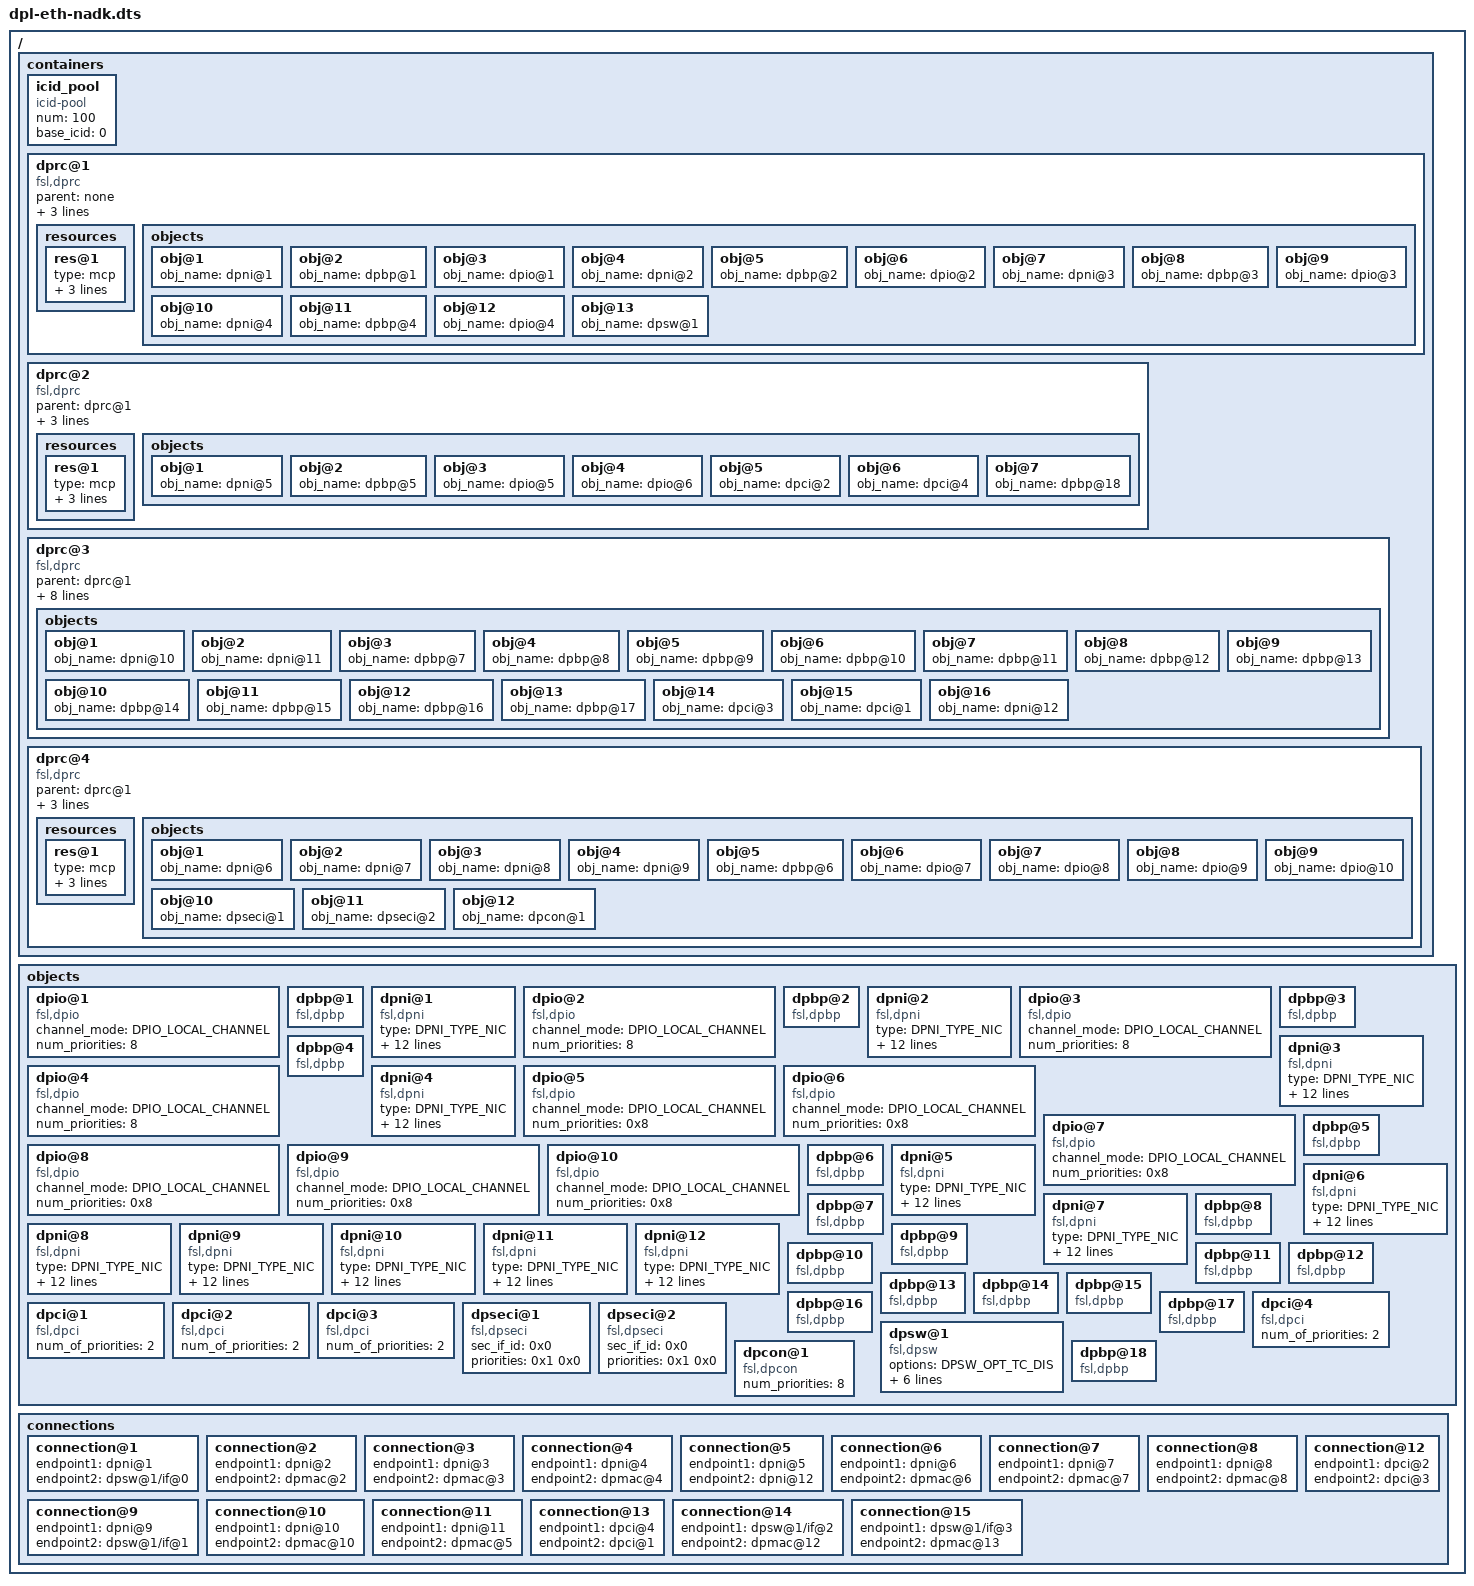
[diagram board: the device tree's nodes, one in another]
/*
 * Datapath layout file for LS2085A.
 * Contains 4 containers-- one for host Linux, two for NADK & one for AIOP
 *
 * Copyright 2013 Freescale Semiconductor, Inc.
 */

/dts-v1/;
/ {
	containers {
		icid_pool {
			compatible = "icid-pool";
			num = <100>;
			base_icid = <0>;
		};
		dprc@1 {
			compatible = "fsl,dprc";
			parent = "none";
			options = "DPRC_CFG_OPT_SPAWN_ALLOWED" , "DPRC_CFG_OPT_ALLOC_ALLOWED";
			portal_id = <0>;
			resources {
				res@1 {
					type = "mcp";
					num = <16>;
					options = <1>;
					id_base_align = <15>;
				};
			};
			objects {
				obj@1{
					obj_name = "dpni@1";
				};
				obj@2{
					obj_name = "dpbp@1";
				};
				obj@3{
					obj_name = "dpio@1";
				};
				obj@4{
					obj_name = "dpni@2";
				};
				obj@5{
					obj_name = "dpbp@2";
				};
				obj@6{
					obj_name = "dpio@2";
				};
				obj@7{
					obj_name = "dpni@3";
				};
				obj@8{
					obj_name = "dpbp@3";
				};
				obj@9{
					obj_name = "dpio@3";
				};
				obj@10{
					obj_name = "dpni@4";
				};
				obj@11{
					obj_name = "dpbp@4";
				};
				obj@12{
					obj_name = "dpio@4";
				};
				obj@13{
					obj_name = "dpsw@1";
				};
			};
		};

		dprc@2 {
			compatible = "fsl,dprc";
			parent = "dprc@1";
			options = "DPRC_CFG_OPT_SPAWN_ALLOWED", "DPRC_CFG_OPT_ALLOC_ALLOWED";
			portal_id = <0x5>;

			resources {

				res@1 {
					type = "mcp";
					num = <0x1>;
					options = <0x1>;
					id_base_align = <0x2>;
				};
			};

			objects {

				obj@1 {
					obj_name = "dpni@5";
				};

				obj@2 {
					obj_name = "dpbp@5";
				};

				obj@3 {
					obj_name = "dpio@5";
				};

				obj@4 {
					obj_name = "dpio@6";
				};

				obj@5{
					obj_name = "dpci@2";
				};

				obj@6{
					obj_name = "dpci@4";
				};

				obj@7 {
					obj_name = "dpbp@18";
				};

			};
		};

		dprc@3 {
			compatible = "fsl,dprc";
			parent = "dprc@1";
			options = "DPRC_CFG_OPT_TOPOLOGY_CHANGES_ALLOWED" , "DPRC_CFG_OPT_IOMMU_BYPASS" , "DPRC_CFG_OPT_SPAWN_ALLOWED" , "DPRC_CFG_OPT_ALLOC_ALLOWED" , "DPRC_CFG_OPT_AIOP" , "DPRC_CFG_OPT_OBJ_CREATE_ALLOWED";
			portal_id = <0x1>;
			objects {
				obj@1{
					obj_name = "dpni@10";
				};
				obj@2{
					obj_name = "dpni@11";
				};
				obj@3{
					obj_name = "dpbp@7";
				};
				obj@4{
					obj_name = "dpbp@8";
				};
				obj@5{
					obj_name = "dpbp@9";
				};
				obj@6{
					obj_name = "dpbp@10";
				};
				obj@7{
					obj_name = "dpbp@11";
				};
				obj@8{
					obj_name = "dpbp@12";
				};
				obj@9{
					obj_name = "dpbp@13";
				};
				obj@10{
					obj_name = "dpbp@14";
				};
				obj@11{
					obj_name = "dpbp@15";
				};
				obj@12{
					obj_name = "dpbp@16";
				};
				obj@13{
					obj_name = "dpbp@17";
				};
				obj@14{
					obj_name = "dpci@3";
				};
				obj@15{
					obj_name = "dpci@1";
				};
				obj@16{
					obj_name = "dpni@12";
				};
			};
		};

		dprc@4 {
			compatible = "fsl,dprc";
			parent = "dprc@1";
			options = "DPRC_CFG_OPT_SPAWN_ALLOWED", "DPRC_CFG_OPT_ALLOC_ALLOWED";
			portal_id = <0x3>;

			resources {

				res@1 {
					type = "mcp";
					num = <0x1>;
					options = <0x1>;
					id_base_align = <0x4>;
				};
			};

			objects {

				obj@1 {
					obj_name = "dpni@6";
				};

				obj@2 {
					obj_name = "dpni@7";
				};

				obj@3 {
					obj_name = "dpni@8";
				};

				obj@4 {
					obj_name = "dpni@9";
				};

				obj@5 {
					obj_name = "dpbp@6";
				};

				obj@6 {
					obj_name = "dpio@7";
				};

				obj@7 {
					obj_name = "dpio@8";
				};

				obj@8 {
					obj_name = "dpio@9";
				};

				obj@9 {
					obj_name = "dpio@10";
				};
				obj@10 {
					obj_name = "dpseci@1";
				};
				obj@11 {
					obj_name = "dpseci@2";
				};
				obj@12 {
					obj_name = "dpcon@1";
				};
			};
		};
	};

	objects {
		dpio@1 {
			compatible = "fsl,dpio";
			channel_mode = "DPIO_LOCAL_CHANNEL";
			num_priorities = <8>;
		};
		dpbp@1 {
			compatible = "fsl,dpbp";
		};
		dpni@1{
			compatible = "fsl,dpni";
			type = "DPNI_TYPE_NIC";
			mac_addr = <0x02 0x00 0xc0 0xa8 0x47 0x01>;
			max_senders = <0>;
			options = "DPNI_OPT_MULTICAST_FILTER", "DPNI_OPT_UNICAST_FILTER";
			max_tcs = <0>;
			max_dist_per_tc = <0 0 0>;
			max_unicast_filters = <0>;
			max_multicast_filters = <0>;
			max_vlan_filters = <0>;
			max_qos_entries = <0>;
			max_qos_key_size = <0>;
			max_dist_key_size = <0>;
		};
		dpio@2 {
			compatible = "fsl,dpio";
			channel_mode = "DPIO_LOCAL_CHANNEL";
			num_priorities = <8>;
		};
		dpbp@2 {
			compatible = "fsl,dpbp";
		};
		dpni@2 {
			compatible = "fsl,dpni";
			type = "DPNI_TYPE_NIC";
			mac_addr = <0x02 0x00 0xc0 0xa8 0x47 0x02>;
			max_senders = <1>;
			options = "DPNI_OPT_MULTICAST_FILTER", "DPNI_OPT_UNICAST_FILTER";
			max_tcs = <1>;
			max_dist_per_tc = <1 0 0>;
			max_unicast_filters = <0>;
			max_multicast_filters = <0>;
			max_vlan_filters = <0>;
			max_qos_entries = <0>;
			max_qos_key_size = <0>;
			max_dist_key_size = <0>;
		};
		dpio@3 {
			compatible = "fsl,dpio";
			channel_mode = "DPIO_LOCAL_CHANNEL";
			num_priorities = <8>;
		};
		dpbp@3 {
			compatible = "fsl,dpbp";
		};
		dpni@3 {
			compatible = "fsl,dpni";
			type = "DPNI_TYPE_NIC";
			mac_addr = <0x02 0x00 0xc0 0xa8 0x47 0x03>;
			max_senders = <1>;
			options = "DPNI_OPT_MULTICAST_FILTER", "DPNI_OPT_UNICAST_FILTER";
			max_tcs = <1>;
			max_dist_per_tc = <1 0 0>;
			max_unicast_filters = <0>;
			max_multicast_filters = <0>;
			max_vlan_filters = <0>;
			max_qos_entries = <0>;
			max_qos_key_size = <0>;
			max_dist_key_size = <0>;
		};
		dpio@4 {
			compatible = "fsl,dpio";
			channel_mode = "DPIO_LOCAL_CHANNEL";
			num_priorities = <8>;
		};
		dpbp@4 {
			compatible = "fsl,dpbp";
		};
		dpni@4 {
			compatible = "fsl,dpni";
			type = "DPNI_TYPE_NIC";
			mac_addr = <0x02 0x00 0xc0 0xa8 0x47 0x04>;
			max_senders = <1>;
			options = "DPNI_OPT_MULTICAST_FILTER", "DPNI_OPT_UNICAST_FILTER";
			max_tcs = <1>;
			max_dist_per_tc = <1 0 0>;
			max_unicast_filters = <0>;
			max_multicast_filters = <0>;
			max_vlan_filters = <0>;
			max_qos_entries = <0>;
			max_qos_key_size = <0>;
			max_dist_key_size = <0>;
		};

		dpio@5 {
			compatible = "fsl,dpio";
			channel_mode = "DPIO_LOCAL_CHANNEL";
			num_priorities = <0x8>;
		};

		dpio@6 {
			compatible = "fsl,dpio";
			channel_mode = "DPIO_LOCAL_CHANNEL";
			num_priorities = <0x8>;
		};

		dpio@7 {
			compatible = "fsl,dpio";
			channel_mode = "DPIO_LOCAL_CHANNEL";
			num_priorities = <0x8>;
		};

		dpio@8 {
			compatible = "fsl,dpio";
			channel_mode = "DPIO_LOCAL_CHANNEL";
			num_priorities = <0x8>;
		};

		dpio@9 {
			compatible = "fsl,dpio";
			channel_mode = "DPIO_LOCAL_CHANNEL";
			num_priorities = <0x8>;
		};

		dpio@10 {
			compatible = "fsl,dpio";
			channel_mode = "DPIO_LOCAL_CHANNEL";
			num_priorities = <0x8>;
		};

		dpbp@5 {
			compatible = "fsl,dpbp";
		};

		dpbp@6 {
			compatible = "fsl,dpbp";
		};

		dpni@5 {
			compatible = "fsl,dpni";
			type = "DPNI_TYPE_NIC";
			mac_addr = <0x0 0x0 0x5 0x0 0x0 0x5>;
			max_senders = <1>;
			options = "DPNI_OPT_MULTICAST_FILTER" , "DPNI_OPT_UNICAST_FILTER";
			max_tcs = <1>;
			max_dist_per_tc = <1 0 0>;
			max_unicast_filters = <16>;
			max_multicast_filters = <16>;
			max_vlan_filters = <0x0>;
			max_qos_entries = <0x0>;
			max_qos_key_size = <0x0>;
			max_dist_key_size = <0x0>;
		};

		dpni@6 {
			compatible = "fsl,dpni";
			type = "DPNI_TYPE_NIC";
			mac_addr = <0x0 0x0 0x0 0x0 0x0 0x6>;
			max_senders = <1>;
			options = "DPNI_OPT_MULTICAST_FILTER" , "DPNI_OPT_UNICAST_FILTER" , "DPNI_OPT_DIST_HASH";
			max_tcs = <1>;
			max_dist_per_tc = <3>;
			max_unicast_filters = <16>;
			max_multicast_filters = <16>;
			max_vlan_filters = <0x0>;
			max_qos_entries = <0x0>;
			max_qos_key_size = <0x0>;
			max_dist_key_size = <0x0>;
		};

		dpni@7 {
			compatible = "fsl,dpni";
			type = "DPNI_TYPE_NIC";
			mac_addr = <0x0 0x0 0x0 0x0 0x0 0x7>;
			max_senders = <1>;
			options = "DPNI_OPT_MULTICAST_FILTER" , "DPNI_OPT_UNICAST_FILTER" , "DPNI_OPT_DIST_HASH";
			max_tcs = <1>;
			max_dist_per_tc = <3>;
			max_unicast_filters = <16>;
			max_multicast_filters = <16>;
			max_vlan_filters = <0x0>;
			max_qos_entries = <0x0>;
			max_qos_key_size = <0x0>;
			max_dist_key_size = <0x0>;
		};

		dpni@8 {
			compatible = "fsl,dpni";
			type = "DPNI_TYPE_NIC";
			mac_addr = <0x0 0x0 0x0 0x0 0x0 0x8>;
			max_senders = <1>;
			options = "DPNI_OPT_MULTICAST_FILTER" , "DPNI_OPT_UNICAST_FILTER" , "DPNI_OPT_DIST_HASH";
			max_tcs = <1>;
			max_dist_per_tc = <3>;
			max_unicast_filters = <16>;
			max_multicast_filters = <16>;
			max_vlan_filters = <0x0>;
			max_qos_entries = <0x0>;
			max_qos_key_size = <0x0>;
			max_dist_key_size = <0x0>;
		};

		dpni@9 {
			compatible = "fsl,dpni";
			type = "DPNI_TYPE_NIC";
			mac_addr = <0x0 0x0 0x0 0x0 0x0 0x9>;
			max_senders = <1>;
			options = "DPNI_OPT_MULTICAST_FILTER" , "DPNI_OPT_UNICAST_FILTER" , "DPNI_OPT_DIST_HASH";
			max_tcs = <1>;
			max_dist_per_tc = <3>;
			max_unicast_filters = <16>;
			max_multicast_filters = <16>;
			max_vlan_filters = <0x0>;
			max_qos_entries = <0x0>;
			max_qos_key_size = <0x0>;
			max_dist_key_size = <0x0>;
		};

		dpni@10{
			compatible = "fsl,dpni";
			type = "DPNI_TYPE_NIC";
			mac_addr = < 0x0 0x0 0x1 0x0 0x0 0x1 >;
			max_senders = <0>;
			options = "DPNI_OPT_MULTICAST_FILTER" , "DPNI_OPT_UNICAST_FILTER" , "DPNI_OPT_DIST_HASH";
			max_tcs = <0>;
			max_dist_per_tc = < 0 0 0 0 0 0 0 0 >;
			max_unicast_filters = <0>;
			max_multicast_filters = <0>;
			max_vlan_filters = <0>;
			max_qos_entries = <0>;
			max_qos_key_size = <0>;
			max_dist_key_size = <0>;
		};

		dpni@11{
			compatible = "fsl,dpni";
			type = "DPNI_TYPE_NIC";
			mac_addr = < 0x0 0x0 0x2 0x0 0x0 0x2 >;
			max_senders = <0>;
			options = "DPNI_OPT_MULTICAST_FILTER" , "DPNI_OPT_UNICAST_FILTER" , "DPNI_OPT_DIST_HASH";
			max_tcs = <0>;
			max_dist_per_tc = < 0 0 0 0 0 0 0 0 >;
			max_unicast_filters = <0>;
			max_multicast_filters = <0>;
			max_vlan_filters = <0>;
			max_qos_entries = <0>;
			max_qos_key_size = <0>;
			max_dist_key_size = <0>;
		};

		dpni@12 {
			compatible = "fsl,dpni";
			type = "DPNI_TYPE_NIC";
			mac_addr = < 0x0 0x0 0xC 0x0 0x0 0xC >;
			max_senders = <0>;
			options = "DPNI_OPT_MULTICAST_FILTER" , "DPNI_OPT_UNICAST_FILTER";
			max_tcs = <0>;
			max_dist_per_tc = < 0 0 0 0 0 0 0 0 >;
			max_unicast_filters = <0>;
			max_multicast_filters = <0>;
			max_vlan_filters = <0>;
			max_qos_entries = <0>;
			max_qos_key_size = <0>;
			max_dist_key_size = <0>;
		};


		dpbp@7 {
			compatible = "fsl,dpbp";
		};

		dpbp@8 {
			compatible = "fsl,dpbp";
		};

		dpbp@9 {
			compatible = "fsl,dpbp";
		};

		dpbp@10 {
			compatible = "fsl,dpbp";
		};

		dpbp@11 {
			compatible = "fsl,dpbp";
		};

		dpbp@12 {
			compatible = "fsl,dpbp";
		};

		dpbp@13 {
			compatible = "fsl,dpbp";
		};

		dpbp@14 {
			compatible = "fsl,dpbp";
		};

		dpbp@15 {
			compatible = "fsl,dpbp";
		};

		dpbp@16 {
			compatible = "fsl,dpbp";
		};

		dpbp@17 {
			compatible = "fsl,dpbp";
		};

		dpci@4{
			compatible = "fsl,dpci";
			num_of_priorities = <2>;
		};
		dpci@1{
			compatible = "fsl,dpci";
			num_of_priorities = <2>;
		};

		dpci@2{
			compatible = "fsl,dpci";
			num_of_priorities = <2>;
		};
		dpci@3{
			compatible = "fsl,dpci";
			num_of_priorities = <2>;
		};
		dpseci@1 {
			compatible = "fsl,dpseci";
			sec_if_id = <0x0>;
			priorities = <0x1 0x0>;
		};
		dpseci@2 {
			compatible = "fsl,dpseci";
			sec_if_id = <0x0>;
			priorities = <0x1 0x0>;
		};

		dpsw@1 {
			compatible = "fsl,dpsw";
			options = "DPSW_OPT_TC_DIS";
			max_vlans = <0x10>;
			max_fdbs = <0x1>;
			num_fdb_entries = <0x400>;
			fdb_aging_time = <0x12c>;
			num_ifs = <0x4>;
			max_fdb_mc_groups = <32>;
		};
		dpcon@1 {
			compatible = "fsl,dpcon";
			num_priorities = <8>;
		};

		dpbp@18 {
			compatible = "fsl,dpbp";
		};

	};

	connections {
		connection@1{
			endpoint1 = "dpni@1";
			endpoint2 = "dpsw@1/if@0";
		};
		connection@2{
			endpoint1 = "dpni@2";
			endpoint2 = "dpmac@2";
		};
		connection@3{
			endpoint1 = "dpni@3";
			endpoint2 = "dpmac@3";
		};
		connection@4{
			endpoint1 = "dpni@4";
			endpoint2 = "dpmac@4";
		};
		connection@5 {
			endpoint1 = "dpni@5";
			endpoint2 = "dpni@12";
		};
		connection@6{
			endpoint1 = "dpni@6";
			endpoint2 = "dpmac@6";
		};
		connection@7{
			endpoint1 = "dpni@7";
			endpoint2 = "dpmac@7";
		};
		connection@8{
			endpoint1 = "dpni@8";
			endpoint2 = "dpmac@8";
		};
		connection@9{
			endpoint1 = "dpni@9";
			endpoint2 = "dpsw@1/if@1";
		};
		connection@10 {
			endpoint1 = "dpni@10";
			endpoint2 = "dpmac@10";
		};
		connection@11 {
			endpoint1 = "dpni@11";
			endpoint2 = "dpmac@5";
		};
		connection@12 {
			endpoint1 = "dpci@2";
			endpoint2 = "dpci@3";
		};
		connection@13 {
			endpoint1 = "dpci@4";
			endpoint2 = "dpci@1";
		};
		connection@14 {
			endpoint1 = "dpsw@1/if@2";
			endpoint2 = "dpmac@12";
		};
		connection@15 {
			endpoint1 = "dpsw@1/if@3";
			endpoint2 = "dpmac@13";
		};
	};
};
